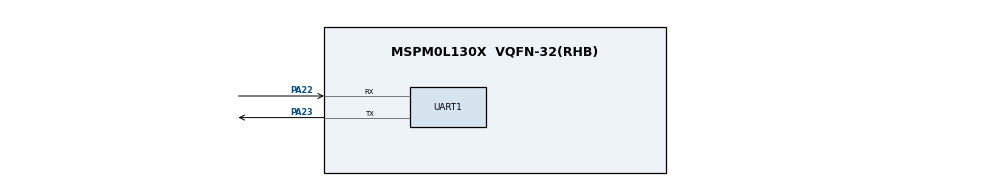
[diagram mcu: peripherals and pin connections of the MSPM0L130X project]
/**
 * @cliArgs --device "MSPM0L130X" --part "Default" --package "VQFN-32(RHB)" --product "mspm0_sdk@2.02.00.05"
 * @versions {"tool":"1.21.0+3721"}
 */

/**
 * Import the modules used in this configuration.
 */
const Board         = scripting.addModule("/ti/driverlib/Board");
const I2C           = scripting.addModule("/ti/driverlib/I2C", {}, false);
const I2C1          = I2C.addInstance();
const SYSCTL        = scripting.addModule("/ti/driverlib/SYSCTL");
const TIMER         = scripting.addModule("/ti/driverlib/TIMER", {}, false);
const TIMER1        = TIMER.addInstance();
const UART          = scripting.addModule("/ti/driverlib/UART", {}, false);
const UART1         = UART.addInstance();
const ProjectConfig = scripting.addModule("/ti/project_config/ProjectConfig");

/**
 * Write custom configuration values to the imported modules.
 */
const gate6  = system.clockTree["MFCLKGATE"];
gate6.enable = true;

const oscillator2           = system.clockTree["SYSOSC"];
oscillator2.frequencySelect = 4;

Board.configureUnused = true;
Board.unusedDirection = "INPUT";

I2C1.$name                             = "I2C";
I2C1.advAnalogGlitchFilter             = "DISABLED";
I2C1.basicEnableController             = true;
I2C1.advControllerTXFIFOTRIG           = "BYTES_1";
I2C1.intController                     = ["ARBITRATION_LOST","NACK","RXFIFO_TRIGGER","RX_DONE","TX_DONE"];
I2C1.interruptPriority                 = "0";
I2C1.peripheral.$assign                = "I2C0";
I2C1.sdaPinConfig.$name                = "ti_driverlib_gpio_GPIOPinGeneric0";
I2C1.sdaPinConfig.hideOutputInversion  = scripting.forceWrite(false);
I2C1.sdaPinConfig.onlyInternalResistor = scripting.forceWrite(false);
I2C1.sdaPinConfig.passedPeripheralType = scripting.forceWrite("Digital");
I2C1.sclPinConfig.$name                = "ti_driverlib_gpio_GPIOPinGeneric1";
I2C1.sclPinConfig.hideOutputInversion  = scripting.forceWrite(false);
I2C1.sclPinConfig.onlyInternalResistor = scripting.forceWrite(false);
I2C1.sclPinConfig.passedPeripheralType = scripting.forceWrite("Digital");

SYSCTL.clockTreeEn = true;
SYSCTL.powerPolicy = "STANDBY1";

TIMER1.$name             = "TIMER_0";
TIMER1.timerClkSrc       = "LFCLK";
TIMER1.timerPeriod       = "1 ms";
TIMER1.timerMode         = "PERIODIC";
TIMER1.timerStartTimer   = true;
TIMER1.interrupts        = ["ZERO"];
TIMER1.interruptPriority = "0";

UART1.$name                      = "UART_0";
UART1.targetBaudRate             = 115200;
UART1.enableFIFO                 = true;
UART1.rxFifoThreshold            = "DL_UART_RX_FIFO_LEVEL_ONE_ENTRY";
UART1.txFifoThreshold            = "DL_UART_TX_FIFO_LEVEL_ONE_ENTRY";
UART1.interruptPriority          = "3";
UART1.enabledInterrupts          = ["DMA_DONE_TX","EOT_DONE","RX"];
UART1.enabledDMATXTriggers       = "DL_UART_DMA_INTERRUPT_TX";
UART1.enableDMARX                = false;
UART1.uartClkSrc                 = "MFCLK";
UART1.peripheral.$assign         = "UART0";
UART1.peripheral.rxPin.$assign   = "PA22";
UART1.peripheral.txPin.$assign   = "PA23";
UART1.txPinConfig.$name          = "ti_driverlib_gpio_GPIOPinGeneric4";
UART1.rxPinConfig.$name          = "ti_driverlib_gpio_GPIOPinGeneric5";
UART1.DMA_CHANNEL_TX.$name       = "DMA_CH0";
UART1.DMA_CHANNEL_TX.addressMode = "b2f";
UART1.DMA_CHANNEL_TX.srcLength   = "BYTE";
UART1.DMA_CHANNEL_TX.dstLength   = "BYTE";

/**
 * Pinmux solution for unlocked pins/peripherals. This ensures that minor changes to the automatic solver in a future
 * version of the tool will not impact the pinmux you originally saw.  These lines can be completely deleted in order to
 * re-solve from scratch.
 */
Board.peripheral.$suggestSolution                = "DEBUGSS";
Board.peripheral.swclkPin.$suggestSolution       = "PA20";
Board.peripheral.swdioPin.$suggestSolution       = "PA19";
I2C1.peripheral.sdaPin.$suggestSolution          = "PA0";
I2C1.peripheral.sclPin.$suggestSolution          = "PA1";
TIMER1.peripheral.$suggestSolution               = "TIMG0";
UART1.DMA_CHANNEL_TX.peripheral.$suggestSolution = "DMA_CH0";
